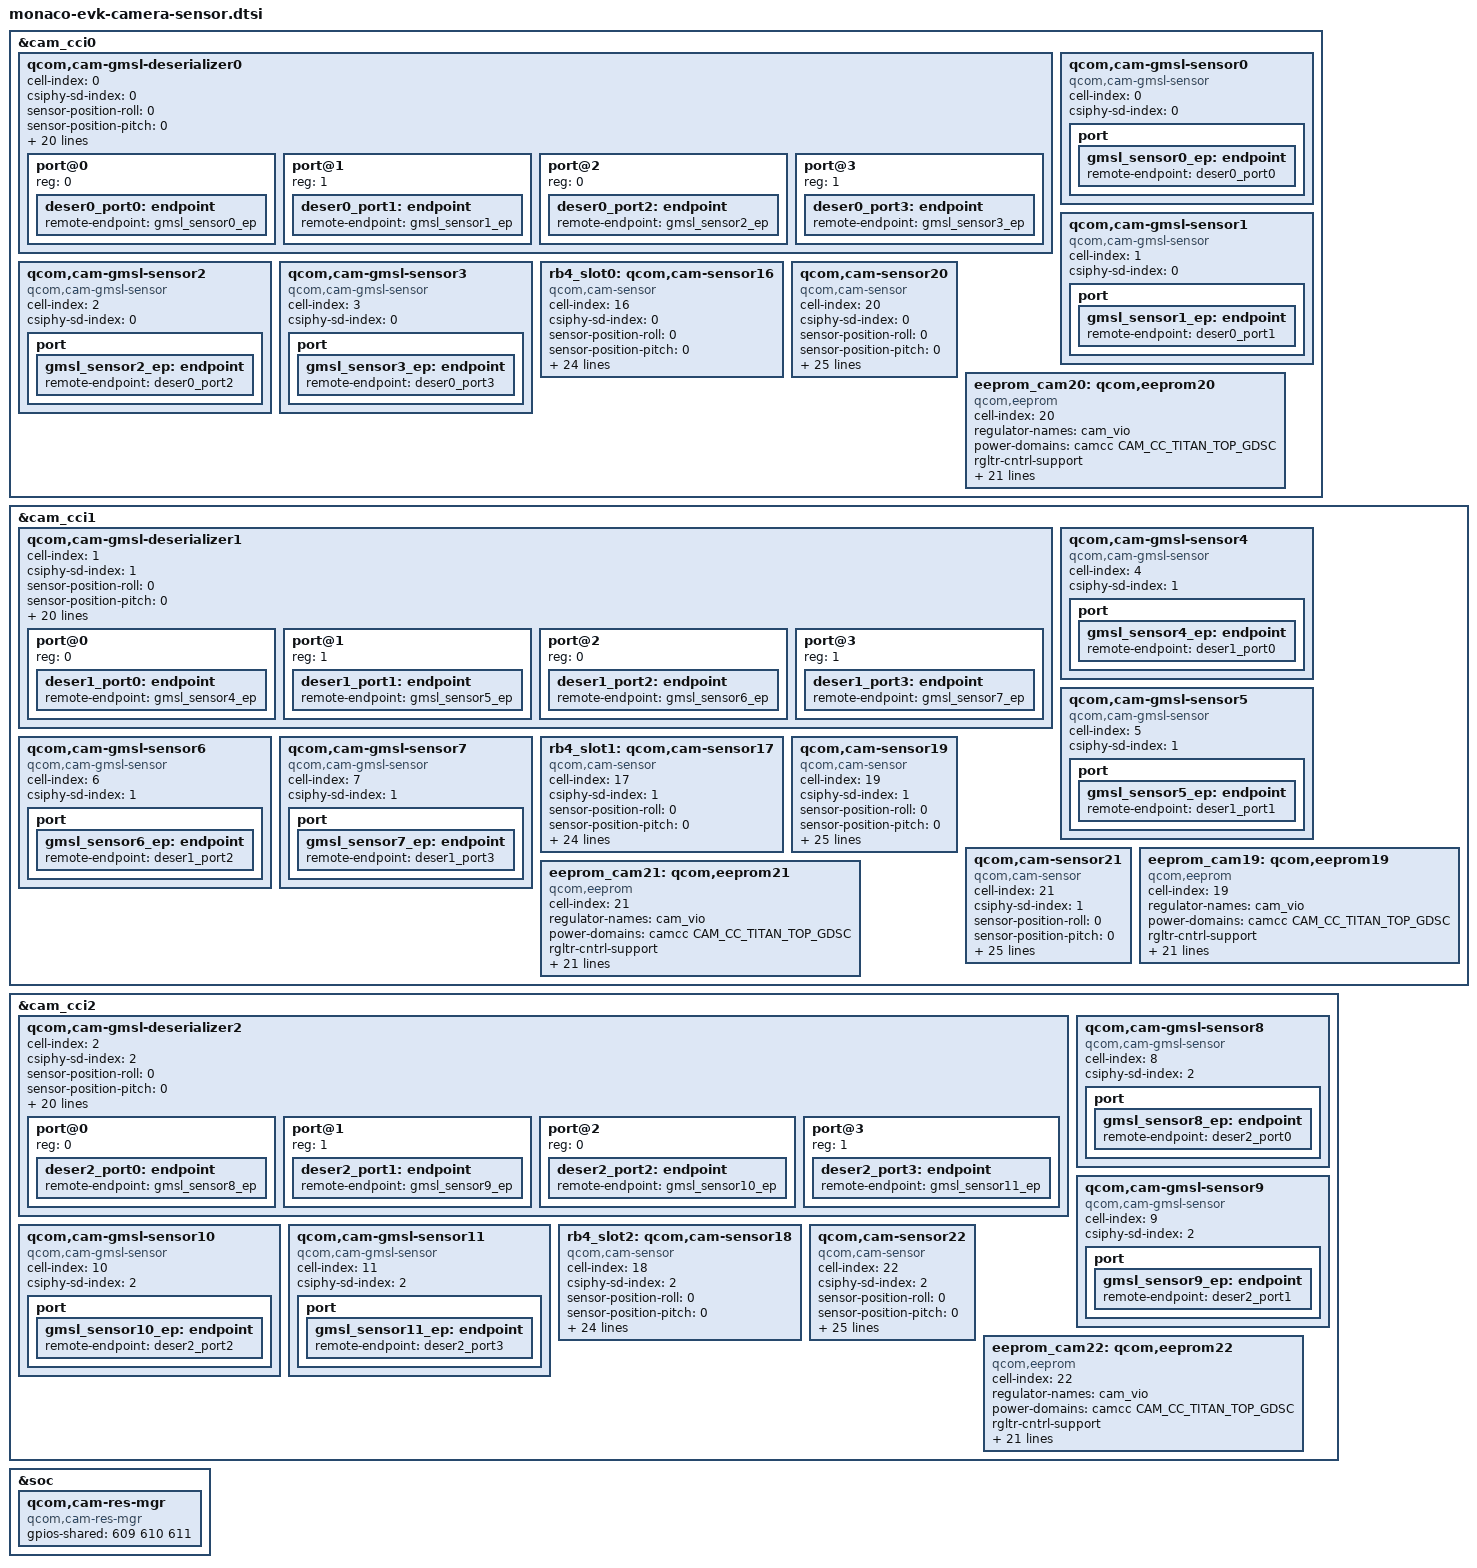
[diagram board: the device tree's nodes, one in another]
// SPDX-License-Identifier: BSD-3-Clause
/*
 * Copyright (c) Qualcomm Technologies, Inc. and/or its subsidiaries.
 */

#include <dt-bindings/camera/msm-camera.h>

&cam_cci0 {
	/* GMSL deserializer 0 */
	qcom,cam-gmsl-deserializer0 {
		cell-index = <0>;
		csiphy-sd-index = <0>;
		sensor-position-roll = <0>;
		sensor-position-pitch = <0>;
		sensor-position-yaw = <180>;
		regulator-names = "cam_vio";
		power-domains = <&camcc CAM_CC_TITAN_TOP_GDSC>;
		rgltr-cntrl-support;
		pwm-switch;
		rgltr-min-voltage = <1800000>;
		rgltr-max-voltage = <1800000>;
		rgltr-load-current = <120000>;
		gpio-no-mux = <0>;
		pinctrl-0 = <&cam_sensor_mclk0_active>;
		pinctrl-1 = <&cam_sensor_mclk0_suspend>;
		pinctrl-names = "cam_default", "cam_suspend";
		gpios = <&tlmm 73 0>;
		gpio-reset = <0>;
		gpio-req-tbl-num = <0>;
		gpio-req-tbl-flags = <0>;
		gpio-req-tbl-label = "CAM_RESET0";
		cci-master = <0>;
		clocks = <&camcc CAM_CC_MCLK0_CLK>;
		clock-names = "cam_clk";
		clock-cntl-level = "nominal";
		clock-rates = <24000000>;
		status = "ok";

		port@0 {
			reg = <0>;

			deser0_port0: endpoint {
				remote-endpoint = <&gmsl_sensor0_ep>;
			};
		};

		port@1 {
			reg = <1>;

			deser0_port1: endpoint {
				remote-endpoint = <&gmsl_sensor1_ep>;
			};
		};

		port@2 {
			reg = <0>;

			deser0_port2: endpoint {
				remote-endpoint = <&gmsl_sensor2_ep>;
			};
		};

		port@3 {
			reg = <1>;

			deser0_port3: endpoint {
				remote-endpoint = <&gmsl_sensor3_ep>;
			};
		};
	};

	/* GMSL deserializer 0 sensor 0 */
	qcom,cam-gmsl-sensor0 {
		compatible = "qcom,cam-gmsl-sensor";
		cell-index = <0>;
		csiphy-sd-index = <0>;
		status = "ok";

		port {
			gmsl_sensor0_ep: endpoint {
				remote-endpoint = <&deser0_port0>;
			};
		};
	};

	/* GMSL deserializer 0 sensor 1 */
	qcom,cam-gmsl-sensor1 {
		compatible = "qcom,cam-gmsl-sensor";
		cell-index = <1>;
		csiphy-sd-index = <0>;
		status = "ok";

		port {
			gmsl_sensor1_ep: endpoint {
				remote-endpoint = <&deser0_port1>;
			};
		};
	};

	/* GMSL deserializer 0 sensor 2 */
	qcom,cam-gmsl-sensor2 {
		compatible = "qcom,cam-gmsl-sensor";
		cell-index = <2>;
		csiphy-sd-index = <0>;
		status = "ok";

		port {
			gmsl_sensor2_ep: endpoint {
				remote-endpoint = <&deser0_port2>;
			};
		};
	};

	/* GMSL deserializer 0 sensor 3 */
	qcom,cam-gmsl-sensor3 {
		compatible = "qcom,cam-gmsl-sensor";
		cell-index = <3>;
		csiphy-sd-index = <0>;
		status = "ok";

		port {
			gmsl_sensor3_ep: endpoint {
				remote-endpoint = <&deser0_port3>;
			};
		};
	};

	/*cam0-ov9282*/
	rb4_slot0: qcom,cam-sensor16 {
		compatible = "qcom,cam-sensor";
		cell-index = <16>;
		csiphy-sd-index = <0>;
		sensor-position-roll = <0>;
		sensor-position-pitch = <0>;
		sensor-position-yaw = <180>;
		regulator-names = "cam_vio";
		power-domains = <&camcc CAM_CC_TITAN_TOP_GDSC>;
		rgltr-cntrl-support;
		pwm-switch;
		rgltr-min-voltage = <1800000>;
		rgltr-max-voltage = <1800000>;
		rgltr-load-current = <120000>;
		gpio-no-mux = <0>;
		pinctrl-0 = <&cam_sensor_mclk0_active
			     &cam_sensor_active_rst0>;
		pinctrl-1 = <&cam_sensor_mclk0_suspend
			     &cam_sensor_suspend_rst0>;
		pinctrl-names = "cam_default", "cam_suspend";
		gpios = <&tlmm 67 0>,
			<&tlmm 73 0>,
			<&expander2 0 0>;
		gpio-reset = <1>;
		gpio-custom1 = <2>;
		gpio-req-tbl-num = <0 1 2>;
		gpio-req-tbl-flags   	 = <1 0 0>;
		gpio-req-tbl-label = "CAM_MCLK0",
				     "CAMIF_RESET0",
			             "CAM_CUSTOM1";
		cci-master = <0>;
		clocks = <&camcc CAM_CC_MCLK0_CLK>;
		clock-names = "cam_clk";
		clock-cntl-level = "nominal";
		clock-rates = <24000000>;
		status = "ok";
	};

	/*cam0-imx577*/
	qcom,cam-sensor20 {
		compatible = "qcom,cam-sensor";
		cell-index = <20>;
		csiphy-sd-index = <0>;
		sensor-position-roll = <0>;
		sensor-position-pitch = <0>;
		sensor-position-yaw = <180>;
		eeprom-src = <&eeprom_cam20>;
		regulator-names = "cam_vio";
		power-domains = <&camcc CAM_CC_TITAN_TOP_GDSC>;
		rgltr-cntrl-support;
		pwm-switch;
		rgltr-min-voltage = <1800000>;
		rgltr-max-voltage = <1800000>;
		rgltr-load-current = <120000>;
		gpio-no-mux = <0>;
		pinctrl-0 = <&cam_sensor_mclk0_active
		             &cam_sensor_active_rst0>;
		pinctrl-1 = <&cam_sensor_mclk0_suspend
		             &cam_sensor_suspend_rst0>;
		pinctrl-names = "cam_default", "cam_suspend";
		gpios = <&tlmm 67 0>,
			<&tlmm 73 0>,
			<&expander2 0 0>;
		gpio-reset = <1>;
		gpio-custom1 = <2>;
		gpio-req-tbl-num = <0 1 2>;
		gpio-req-tbl-flags   	 = <1 0 0>;
		gpio-req-tbl-label = "CAM_MCLK0",
				     "CAMIF_RESET0",
				     "CAM_CUSTOM1";
		cci-master = <0>;
		clocks = <&camcc CAM_CC_MCLK0_CLK>;
		clock-names = "cam_clk";
		clock-cntl-level = "nominal";
		clock-rates = <24000000>;
		status = "ok";
	};

	eeprom_cam20: qcom,eeprom20 {
		cell-index = <20>;
		compatible = "qcom,eeprom";
		regulator-names = "cam_vio";
		power-domains = <&camcc CAM_CC_TITAN_TOP_GDSC>;
		rgltr-cntrl-support;
		pwm-switch;
		rgltr-min-voltage = <1800000>;
		rgltr-max-voltage = <1800000>;
		rgltr-load-current = <120000>;
		gpio-no-mux = <0>;
		pinctrl-0 = <&cam_sensor_mclk0_active
			     &cam_sensor_active_rst0>;
		pinctrl-1 = <&cam_sensor_mclk0_suspend
			     &cam_sensor_suspend_rst0>;
		pinctrl-names = "cam_default", "cam_suspend";
		gpios = <&tlmm 67 0>,
			<&tlmm 73 0>,
			<&expander2 0 0>;
		gpio-reset = <1>;
		gpio-custom1 = <2>;
		gpio-req-tbl-num = <0 1 2>;
		gpio-req-tbl-flags = <1 0 0>;
		gpio-req-tbl-label = "CAM_MCLK0",
				     "CAMIF_RESET0",
				     "CAM_CUSTOM1";
		sensor-mode = <0>;
		cci-master = <0>;
		status = "ok";
		clocks = <&camcc CAM_CC_MCLK0_CLK>;
		clock-names = "cam_clk";
		clock-cntl-level = "nominal";
		clock-rates = <24000000>;
	};
};

&cam_cci1 {
	/* GMSL deserializer 1 */
	qcom,cam-gmsl-deserializer1 {
		cell-index = <1>;
		csiphy-sd-index = <1>;
		sensor-position-roll = <0>;
		sensor-position-pitch = <0>;
		sensor-position-yaw = <180>;
		regulator-names = "cam_vio";
		power-domains = <&camcc CAM_CC_TITAN_TOP_GDSC>;
		rgltr-cntrl-support;
		pwm-switch;
		rgltr-min-voltage = <1800000>;
		rgltr-max-voltage = <1800000>;
		rgltr-load-current = <120000>;
		gpio-no-mux = <0>;
		pinctrl-0 = <&cam_sensor_mclk1_active>;
		pinctrl-1 = <&cam_sensor_mclk1_suspend>;
		pinctrl-names = "cam_default", "cam_suspend";
		gpios = <&tlmm 74 0>;
		gpio-reset = <0>;
		gpio-req-tbl-num = <0>;
		gpio-req-tbl-flags = <0>;
		gpio-req-tbl-label = "CAM_RESET1";
		cci-master = <0>;
		clocks = <&camcc CAM_CC_MCLK1_CLK>;
		clock-names = "cam_clk";
		clock-cntl-level = "nominal";
		clock-rates = <24000000>;
		status = "ok";

		port@0 {
			reg = <0>;

			deser1_port0: endpoint {
				remote-endpoint = <&gmsl_sensor4_ep>;
			};
		};

		port@1 {
			reg = <1>;

			deser1_port1: endpoint {
				remote-endpoint = <&gmsl_sensor5_ep>;
			};
		};

		port@2 {
			reg = <0>;

			deser1_port2: endpoint {
				remote-endpoint = <&gmsl_sensor6_ep>;
			};
		};

		port@3 {
			reg = <1>;

			deser1_port3: endpoint {
				remote-endpoint = <&gmsl_sensor7_ep>;
			};
		};
	};

	/* GMSL deserializer 1 sensor 0 */
	qcom,cam-gmsl-sensor4 {
		compatible = "qcom,cam-gmsl-sensor";
		cell-index = <4>;
		csiphy-sd-index = <1>;
		status = "ok";

		port {
			gmsl_sensor4_ep: endpoint {
				remote-endpoint = <&deser1_port0>;
			};
		};
	};

	/* GMSL deserializer 1 sensor 1 */
	qcom,cam-gmsl-sensor5 {
		compatible = "qcom,cam-gmsl-sensor";
		cell-index = <5>;
		csiphy-sd-index = <1>;
		status = "ok";

		port {
			gmsl_sensor5_ep: endpoint {
				remote-endpoint = <&deser1_port1>;
			};
		};
	};

	/* GMSL deserializer 1 sensor 2 */
	qcom,cam-gmsl-sensor6 {
		compatible = "qcom,cam-gmsl-sensor";
		cell-index = <6>;
		csiphy-sd-index = <1>;
		status = "ok";

		port {
			gmsl_sensor6_ep: endpoint {
				remote-endpoint = <&deser1_port2>;
			};
		};
	};

	/* GMSL deserializer 1 sensor 3 */
	qcom,cam-gmsl-sensor7 {
		compatible = "qcom,cam-gmsl-sensor";
		cell-index = <7>;
		csiphy-sd-index = <1>;
		status = "ok";

		port {
			gmsl_sensor7_ep: endpoint {
				remote-endpoint = <&deser1_port3>;
			};
		};
	};

	/*cam1-ov9282*/
	rb4_slot1: qcom,cam-sensor17 {
		compatible = "qcom,cam-sensor";
		cell-index = <17>;
		csiphy-sd-index = <1>;
		sensor-position-roll = <0>;
		sensor-position-pitch = <0>;
		sensor-position-yaw = <180>;
		regulator-names = "cam_vio";
		power-domains = <&camcc CAM_CC_TITAN_TOP_GDSC>;
		rgltr-cntrl-support;
		pwm-switch;
		rgltr-min-voltage = <1800000>;
		rgltr-max-voltage = <1800000>;
		rgltr-load-current = <120000>;
		gpio-no-mux = <0>;
		pinctrl-0 = <&cam_sensor_mclk1_active
			     &cam_sensor_active_rst1>;
		pinctrl-1 = <&cam_sensor_mclk1_suspend
			     &cam_sensor_suspend_rst1>;
		pinctrl-names = "cam_default", "cam_suspend";
		gpios = <&tlmm 68 0>,
			<&tlmm 74 0>,
			<&expander2 1 0>;
		gpio-reset = <1>;
		gpio-custom1 = <2>;
		gpio-req-tbl-num = <0 1 2>;
		gpio-req-tbl-flags   	 = <1 0 0>;
		gpio-req-tbl-label = "CAM_MCLK1",
				     "CAMIF_RESET1",
				     "CAM_CUSTOM1";
		cci-master = <0>;
		clocks = <&camcc CAM_CC_MCLK1_CLK>;
		clock-names = "cam_clk";
		clock-cntl-level = "nominal";
		clock-rates = <24000000>;
		status = "ok";
	};

	/*cam0-imx577*/
	qcom,cam-sensor19 {
		compatible = "qcom,cam-sensor";
		cell-index = <19>;
		csiphy-sd-index = <1>;
		sensor-position-roll = <0>;
		sensor-position-pitch = <0>;
		sensor-position-yaw = <180>;
		eeprom-src = <&eeprom_cam19>;
		regulator-names = "cam_vio";
		power-domains = <&camcc CAM_CC_TITAN_TOP_GDSC>;
		rgltr-cntrl-support;
		pwm-switch;
		rgltr-min-voltage = <1800000>;
		rgltr-max-voltage = <1800000>;
		rgltr-load-current = <120000>;
		gpio-no-mux = <0>;
		pinctrl-0 = <&cam_sensor_mclk1_active
			     &cam_sensor_active_rst1>;
		pinctrl-1 = <&cam_sensor_mclk1_suspend
			     &cam_sensor_suspend_rst1>;
		pinctrl-names = "cam_default", "cam_suspend";
		gpios = <&tlmm 68 0>,
			<&tlmm 74 0>,
			<&expander2 1 0>;
		gpio-reset = <1>;
		gpio-custom1 = <2>;
		gpio-req-tbl-num = <0 1 2>;
		gpio-req-tbl-flags = <1 0 0>;
		gpio-req-tbl-label = "CAM_MCLK1",
				     "CAMIF_RESET1",
				     "CAM_CUSTOM1";
		cci-master = <0>;
		clocks = <&camcc CAM_CC_MCLK1_CLK>;
		clock-names = "cam_clk";
		clock-cntl-level = "nominal";
		clock-rates = <24000000>;
		status = "ok";
	};

	/*cam0-imx577*/
	qcom,cam-sensor21 {
		compatible = "qcom,cam-sensor";
		cell-index = <21>;
		csiphy-sd-index = <1>;
		sensor-position-roll = <0>;
		sensor-position-pitch = <0>;
		sensor-position-yaw = <180>;
		eeprom-src = <&eeprom_cam21>;
		regulator-names = "cam_vio";
		power-domains = <&camcc CAM_CC_TITAN_TOP_GDSC>;
		rgltr-cntrl-support;
		pwm-switch;
		rgltr-min-voltage = <1800000>;
		rgltr-max-voltage = <1800000>;
		rgltr-load-current = <120000>;
		gpio-no-mux = <0>;
		pinctrl-0 = <&cam_sensor_mclk1_active
			     &cam_sensor_active_rst1>;
		pinctrl-1 = <&cam_sensor_mclk1_suspend
			     &cam_sensor_suspend_rst1>;
		pinctrl-names = "cam_default", "cam_suspend";
		gpios = <&tlmm 68 0>,
			<&tlmm 74 0>,
			<&expander2 1 0>;
		gpio-reset = <1>;
		gpio-custom1 = <2>;
		gpio-req-tbl-num = <0 1 2>;
		gpio-req-tbl-flags = <1 0 0>;
		gpio-req-tbl-label = "CAM_MCLK1",
				     "CAMIF_RESET1",
				     "CAM_CUSTOM1";
		cci-master = <0>;
		clocks = <&camcc CAM_CC_MCLK1_CLK>;
		clock-names = "cam_clk";
		clock-cntl-level = "nominal";
		clock-rates = <24000000>;
		status = "ok";
	};

	eeprom_cam19: qcom,eeprom19 {
		compatible = "qcom,eeprom";
		cell-index = <19>;
		regulator-names = "cam_vio";
		power-domains = <&camcc CAM_CC_TITAN_TOP_GDSC>;
		rgltr-cntrl-support;
		pwm-switch;
		rgltr-min-voltage = <1800000>;
		rgltr-max-voltage = <1800000>;
		rgltr-load-current = <120000>;
		gpio-no-mux = <0>;
		pinctrl-0 = <&cam_sensor_mclk1_active
			     &cam_sensor_active_rst1>;
		pinctrl-1 = <&cam_sensor_mclk1_suspend
			     &cam_sensor_suspend_rst1>;
		pinctrl-names = "cam_default", "cam_suspend";
		gpios = <&tlmm 68 0>,
			<&tlmm 74 0>,
			<&expander2 1 0>;
		gpio-reset = <1>;
		gpio-custom1 = <2>;
		gpio-req-tbl-num = <0 1 2>;
		gpio-req-tbl-flags = <1 0 0>;
		gpio-req-tbl-label = "CAM_MCLK1",
				     "CAMIF_RESET1",
				     "CAM_CUSTOM1";
		sensor-mode = <0>;
		cci-master = <0>;
		clocks = <&camcc CAM_CC_MCLK1_CLK>;
		clock-names = "cam_clk";
		clock-cntl-level = "nominal";
		clock-rates = <24000000>;
		status = "ok";
	};

	eeprom_cam21: qcom,eeprom21 {
		compatible = "qcom,eeprom";
		cell-index = <21>;
		regulator-names = "cam_vio";
		power-domains = <&camcc CAM_CC_TITAN_TOP_GDSC>;
		rgltr-cntrl-support;
		pwm-switch;
		rgltr-min-voltage = <1800000>;
		rgltr-max-voltage = <1800000>;
		rgltr-load-current = <120000>;
		gpio-no-mux = <0>;
		pinctrl-0 = <&cam_sensor_mclk1_active
			     &cam_sensor_active_rst1>;
		pinctrl-1 = <&cam_sensor_mclk1_suspend
			     &cam_sensor_suspend_rst1>;
		pinctrl-names = "cam_default", "cam_suspend";
		gpios = <&tlmm 68 0>,
			<&tlmm 74 0>,
			<&expander2 1 0>;
		gpio-reset = <1>;
		gpio-custom1 = <2>;
		gpio-req-tbl-num = <0 1 2>;
		gpio-req-tbl-flags = <1 0 0>;
		gpio-req-tbl-label = "CAM_MCLK1",
				     "CAMIF_RESET1",
				     "CAM_CUSTOM1";
		sensor-mode = <0>;
		cci-master = <0>;
		clocks = <&camcc CAM_CC_MCLK1_CLK>;
		clock-names = "cam_clk";
		clock-cntl-level = "nominal";
		clock-rates = <24000000>;
		status = "ok";
	};
};

&cam_cci2 {
	/* GMSL deserializer 2 */
	qcom,cam-gmsl-deserializer2 {
		cell-index = <2>;
		csiphy-sd-index = <2>;
		sensor-position-roll = <0>;
		sensor-position-pitch = <0>;
		sensor-position-yaw = <180>;
		regulator-names = "cam_vio";
		power-domains = <&camcc CAM_CC_TITAN_TOP_GDSC>;
		rgltr-cntrl-support;
		pwm-switch;
		rgltr-min-voltage = <1800000>;
		rgltr-max-voltage = <1800000>;
		rgltr-load-current = <120000>;
		gpio-no-mux = <0>;
		pinctrl-0 = <&cam_sensor_mclk2_active>;
		pinctrl-1 = <&cam_sensor_mclk2_suspend>;
		pinctrl-names = "cam_default", "cam_suspend";
		gpios = <&tlmm 75 0>;
		gpio-reset = <0>;
		gpio-req-tbl-num = <0>;
		gpio-req-tbl-flags = <0>;
		gpio-req-tbl-label = "CAM_RESET2";
		cci-master = <0>;
		clocks = <&camcc CAM_CC_MCLK2_CLK>;
		clock-names = "cam_clk";
		clock-cntl-level = "nominal";
		clock-rates = <24000000>;
		status = "ok";

		port@0 {
			reg = <0>;

			deser2_port0: endpoint {
				remote-endpoint = <&gmsl_sensor8_ep>;
			};
		};

		port@1 {
			reg = <1>;

			deser2_port1: endpoint {
				remote-endpoint = <&gmsl_sensor9_ep>;
			};
		};

		port@2 {
			reg = <0>;

			deser2_port2: endpoint {
				remote-endpoint = <&gmsl_sensor10_ep>;
			};
		};

		port@3 {
			reg = <1>;

			deser2_port3: endpoint {
				remote-endpoint = <&gmsl_sensor11_ep>;
			};
		};
	};

	/* GMSL deserializer 2 sensor 0 */
	qcom,cam-gmsl-sensor8 {
		compatible = "qcom,cam-gmsl-sensor";
		cell-index = <8>;
		csiphy-sd-index = <2>;
		status = "ok";

		port {
			gmsl_sensor8_ep: endpoint {
				remote-endpoint = <&deser2_port0>;
			};
		};
	};

	/* GMSL deserializer 2 sensor 1 */
	qcom,cam-gmsl-sensor9 {
		compatible = "qcom,cam-gmsl-sensor";
		cell-index = <9>;
		csiphy-sd-index = <2>;
		status = "ok";

		port {
			gmsl_sensor9_ep: endpoint {
				remote-endpoint = <&deser2_port1>;
			};
		};
	};

	/* GMSL deserializer 2 sensor 2 */
	qcom,cam-gmsl-sensor10 {
		compatible = "qcom,cam-gmsl-sensor";
		cell-index = <10>;
		csiphy-sd-index = <2>;
		status = "ok";

		port {
			gmsl_sensor10_ep: endpoint {
				remote-endpoint = <&deser2_port2>;
			};
		};
	};

	/* GMSL deserializer 2 sensor 3 */
	qcom,cam-gmsl-sensor11 {
		compatible = "qcom,cam-gmsl-sensor";
		cell-index = <11>;
		csiphy-sd-index = <2>;
		status = "ok";

		port {
			gmsl_sensor11_ep: endpoint {
				remote-endpoint = <&deser2_port3>;
			};
		};
	};

	/*cam2-ov9282*/
	rb4_slot2: qcom,cam-sensor18 {
		compatible = "qcom,cam-sensor";
		cell-index = <18>;
		csiphy-sd-index = <2>;
		sensor-position-roll = <0>;
		sensor-position-pitch = <0>;
		sensor-position-yaw = <180>;
		regulator-names = "cam_vio";
		power-domains = <&camcc CAM_CC_TITAN_TOP_GDSC>;
		rgltr-cntrl-support;
		pwm-switch;
		rgltr-min-voltage = <1800000>;
		rgltr-max-voltage = <1800000>;
		rgltr-load-current = <120000>;
		gpio-no-mux = <0>;
		pinctrl-0 = <&cam_sensor_mclk2_active
			     &cam_sensor_active_rst2>;
		pinctrl-1 = <&cam_sensor_mclk2_suspend
			     &cam_sensor_suspend_rst2>;
		pinctrl-names = "cam_default", "cam_suspend";
		gpios = <&tlmm 69 0>,
			<&tlmm 75 0>,
			<&expander2 2 0>;
		gpio-reset = <1>;
		gpio-custom1 = <2>;
		gpio-req-tbl-num = <0 1 2>;
		gpio-req-tbl-flags = <1 0 0>;
		gpio-req-tbl-label = "CAM_MCLK2",
				     "CAMIF_RESET2",
				     "CAM_CUSTOM1";
		cci-master = <0>;
		clocks = <&camcc CAM_CC_MCLK2_CLK>;
		clock-names = "cam_clk";
		clock-cntl-level = "nominal";
		clock-rates = <24000000>;
		status = "ok";
	};

	/*cam2-imx577*/
	qcom,cam-sensor22 {
		compatible = "qcom,cam-sensor";
		cell-index = <22>;
		csiphy-sd-index = <2>;
		sensor-position-roll = <0>;
		sensor-position-pitch = <0>;
		sensor-position-yaw = <180>;
		eeprom-src = <&eeprom_cam22>;
		regulator-names = "cam_vio";
		power-domains = <&camcc CAM_CC_TITAN_TOP_GDSC>;
		rgltr-cntrl-support;
		pwm-switch;
		rgltr-min-voltage = <1800000>;
		rgltr-max-voltage = <1800000>;
		rgltr-load-current = <120000>;
		gpio-no-mux = <0>;
		pinctrl-0 = <&cam_sensor_mclk2_active
			     &cam_sensor_active_rst2>;
		pinctrl-1 = <&cam_sensor_mclk2_suspend
			     &cam_sensor_suspend_rst2>;
		pinctrl-names = "cam_default", "cam_suspend";
		gpios = <&tlmm 69 0>,
			<&tlmm 75 0>,
			<&expander2 2 0>;
		gpio-reset = <1>;
		gpio-custom1 = <2>;
		gpio-req-tbl-num = <0 1 2>;
		gpio-req-tbl-flags   	 = <1 0 0>;
		gpio-req-tbl-label = "CAM_MCLK2",
				     "CAMIF_RESET2",
				     "CAM_CUSTOM1";
		cci-master = <0>;
		clocks = <&camcc CAM_CC_MCLK2_CLK>;
		clock-names = "cam_clk";
		clock-cntl-level = "nominal";
		clock-rates = <24000000>;
		status = "ok";
	};

	eeprom_cam22: qcom,eeprom22 {
		compatible = "qcom,eeprom";
		cell-index = <22>;
		regulator-names = "cam_vio";
		power-domains = <&camcc CAM_CC_TITAN_TOP_GDSC>;
		rgltr-cntrl-support;
		pwm-switch;
		rgltr-min-voltage = <1800000>;
		rgltr-max-voltage = <1800000>;
		rgltr-load-current = <120000>;
		gpio-no-mux = <0>;
		pinctrl-0 = <&cam_sensor_mclk2_active
			     &cam_sensor_active_rst2>;
		pinctrl-1 = <&cam_sensor_mclk2_suspend
			     &cam_sensor_suspend_rst2>;
		pinctrl-names = "cam_default", "cam_suspend";
		gpios = <&tlmm 69 0>,
			<&tlmm 75 0>,
			<&expander2 2 0>;
		gpio-reset = <1>;
		gpio-custom1 = <2>;
		gpio-req-tbl-num = <0 1 2>;
		gpio-req-tbl-flags = <1 0 0>;
		gpio-req-tbl-label = "CAM_MCLK2",
				     "CAMIF_RESET2",
				     "CAM_CUSTOM1";
		sensor-mode = <0>;
		cci-master = <0>;
		clocks = <&camcc CAM_CC_MCLK2_CLK>;
		clock-names = "cam_clk";
		clock-cntl-level = "nominal";
		clock-rates = <24000000>;
		status = "ok";
	};
};

&soc {
	qcom,cam-res-mgr {
		compatible = "qcom,cam-res-mgr";
		status = "ok";
		gpios-shared = <609 610 611>;
	};
};
